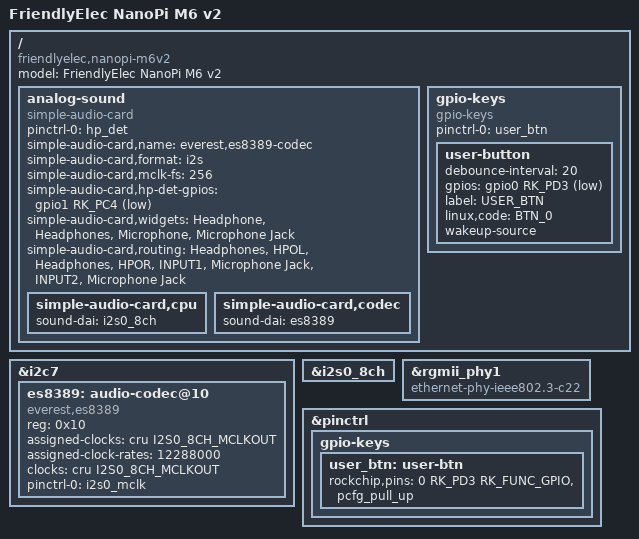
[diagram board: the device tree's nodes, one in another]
// SPDX-License-Identifier: (GPL-2.0+ OR MIT)

/dts-v1/;

#include "rk3588s-nanopi-m6.dts"

/delete-node/ &rt5616;

/ {
	model = "FriendlyElec NanoPi M6 v2";
	compatible = "friendlyelec,nanopi-m6v2", "rockchip,rk3588s";

	/delete-node/ analog-sound;

	analog-sound {
		compatible = "simple-audio-card";
		pinctrl-names = "default";
		pinctrl-0 = <&hp_det>;

		simple-audio-card,name = "everest,es8389-codec";
		simple-audio-card,format = "i2s";
		simple-audio-card,mclk-fs = <256>;
		simple-audio-card,hp-det-gpios = <&gpio1 RK_PC4 GPIO_ACTIVE_LOW>;

		simple-audio-card,widgets =
			"Headphone", "Headphones",
			"Microphone", "Microphone Jack";
		simple-audio-card,routing =
			"Headphones", "HPOL",
			"Headphones", "HPOR",
			"INPUT1", "Microphone Jack",
			"INPUT2", "Microphone Jack";

		simple-audio-card,cpu {
			sound-dai = <&i2s0_8ch>;
		};

		simple-audio-card,codec {
			sound-dai = <&es8389>;
		};
	};

	gpio-keys {
		compatible = "gpio-keys";
		pinctrl-names = "default";
		pinctrl-0 = <&user_btn>;

		user-button {
			debounce-interval = <20>;
			gpios = <&gpio0 RK_PD3 GPIO_ACTIVE_LOW>;
			label = "USER_BTN";
			linux,code = <BTN_0>;
			wakeup-source;
		};
	};
};

&i2c7 {
	es8389: audio-codec@10 {
		compatible = "everest,es8389";
		reg = <0x10>;
		assigned-clocks = <&cru I2S0_8CH_MCLKOUT>;
		assigned-clock-rates = <12288000>;
		clocks = <&cru I2S0_8CH_MCLKOUT>;
		clock-names = "mclk";
		pinctrl-names = "default";
		pinctrl-0 = <&i2s0_mclk>;
		#sound-dai-cells = <0>;
	};
};

&i2s0_8ch {
	/delete-node/ port;
};

&rgmii_phy1 {
	compatible = "ethernet-phy-ieee802.3-c22";
};

&pinctrl {
	gpio-keys {
		user_btn: user-btn {
			rockchip,pins = <0 RK_PD3 RK_FUNC_GPIO &pcfg_pull_up>;
		};
	};
};
